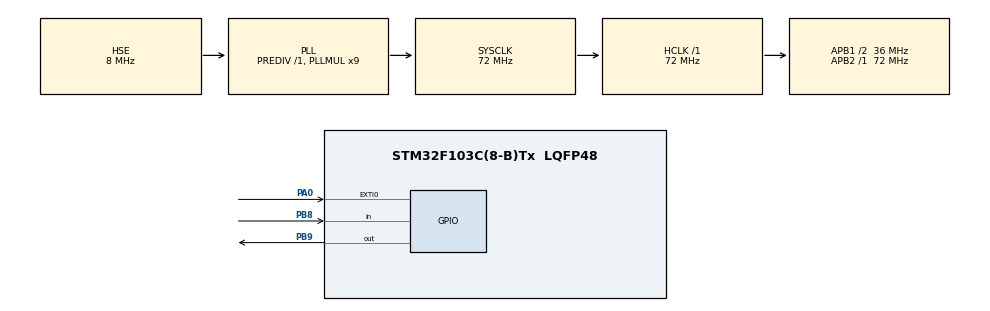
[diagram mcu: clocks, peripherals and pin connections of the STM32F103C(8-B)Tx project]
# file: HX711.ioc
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Mcu.Family=STM32F1
Mcu.Name=STM32F103C(8-B)Tx
Mcu.Package=LQFP48
NVIC.PriorityGroup=NVIC_PRIORITYGROUP_4
NVIC.TIM3_IRQn=true\:0\:0\:false\:false\:true\:true\:true\:true
PA0-WKUP.GPIO_ModeDefaultEXTI=GPIO_MODE_IT_FALLING
PA0-WKUP.Signal=GPXTI0
PA13.Mode=Serial_Wire
PA13.Signal=SYS_JTMS-SWDIO
PA14.Mode=Serial_Wire
PA14.Signal=SYS_JTCK-SWCLK
PB8.Signal=GPIO_Input
PB9.Signal=GPIO_Output
PD0-OSC_IN.Mode=HSE-External-Oscillator
PD0-OSC_IN.Signal=RCC_OSC_IN
PD1-OSC_OUT.Mode=HSE-External-Oscillator
PD1-OSC_OUT.Signal=RCC_OSC_OUT
ProjectManager.HeapSize=0x200
ProjectManager.StackSize=0x400
ProjectManager.TargetToolchain=STM32CubeIDE
RCC.AHBFreq_Value=72000000
RCC.APB1CLKDivider=RCC_HCLK_DIV2
RCC.APB1Freq_Value=36000000
RCC.APB1TimFreq_Value=72000000
RCC.APB2Freq_Value=72000000
RCC.APB2TimFreq_Value=72000000
RCC.HCLKFreq_Value=72000000
RCC.PLLMUL=RCC_PLL_MUL9
RCC.PLLSourceVirtual=RCC_PLLSOURCE_HSE
RCC.SYSCLKFreq_VALUE=72000000
RCC.SYSCLKSource=RCC_SYSCLKSOURCE_PLLCLK
RCC.USBFreq_Value=72000000
TIM2.Prescaler=71
TIM3.Period=9999
TIM3.Prescaler=7199
VP_TIM2_VS_ClockSourceINT.Mode=Internal
VP_TIM3_VS_ClockSourceINT.Mode=Internal
board=custom

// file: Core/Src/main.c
/* USER CODE BEGIN Header */
/**
  ******************************************************************************
  * @file           : main.c
  * @brief          : Main program body
  ******************************************************************************
  * @attention
  *
  * Copyright (c) 2025 STMicroelectronics.
  * All rights reserved.
  *
  * This software is licensed under terms that can be found in the LICENSE file
  * in the root directory of this software component.
  * If no LICENSE file comes with this software, it is provided AS-IS.
  *
  ******************************************************************************
  */
/* USER CODE END Header */
#include "main.h"

/* USER CODE BEGIN PD */
#define DT_PIN GPIO_PIN_8
#define DT_PORT GPIOB
#define SCK_PIN GPIO_PIN_9
#define SCK_PORT GPIOB
/* USER CODE END PD */

TIM_HandleTypeDef htim2;
TIM_HandleTypeDef htim3;

/* USER CODE BEGIN PV */
uint32_t tare = 8645755;
float knownOriginal = 74000;  // in milli gram
float knownHX711 = 30108;
int weight;

volatile uint32_t pulse_count = 0; // Biến đếm xung từ cảm biến
float rpm = 0.0f;                  // Biến lưu giá trị RPM
/* USER CODE END PV */

void SystemClock_Config(void);
static void MX_GPIO_Init(void);
static void MX_TIM2_Init(void);
static void MX_TIM3_Init(void);

/* USER CODE BEGIN 0 */

void HAL_GPIO_EXTI_Callback(uint16_t GPIO_Pin)
{
  if(GPIO_Pin == GPIO_PIN_0) // Kiểm tra xem có phải là ngắt từ chân PA0 không
  {
    pulse_count++; // Nếu đúng, tăng biến đếm xung lên 1
  }
}

void HAL_TIM_PeriodElapsedCallback(TIM_HandleTypeDef *htim)
{
  if (htim->Instance == TIM3) // Kiểm tra xem có phải ngắt từ TIM2 không
  {
    // Công thức: RPM = (Số xung / giây) * 60
    // Vì timer ngắt mỗi 1 giây, nên số xung/giây chính là pulse_count
    rpm = pulse_count * 60;

    // Reset biến đếm để bắt đầu chu kỳ đo mới
    pulse_count = 0;
  }
}

void microDelay(uint16_t delay)
{
  __HAL_TIM_SET_COUNTER(&htim2, 0);
  while (__HAL_TIM_GET_COUNTER(&htim2) < delay);
}

int32_t getHX711(void)
{
  uint32_t data = 0;
  uint32_t startTime = HAL_GetTick();
  while(HAL_GPIO_ReadPin(DT_PORT, DT_PIN) == GPIO_PIN_SET)
  {
    if(HAL_GetTick() - startTime > 200)
      return 0;
  }
  for(int8_t len=0; len<24 ; len++)
  {
    HAL_GPIO_WritePin(SCK_PORT, SCK_PIN, GPIO_PIN_SET);
    microDelay(1);
    data = data << 1;
    HAL_GPIO_WritePin(SCK_PORT, SCK_PIN, GPIO_PIN_RESET);
    microDelay(1);
    if(HAL_GPIO_ReadPin(DT_PORT, DT_PIN) == GPIO_PIN_SET)
      data ++;
  }
  data = data ^ 0x800000;
  HAL_GPIO_WritePin(SCK_PORT, SCK_PIN, GPIO_PIN_SET);
  microDelay(1);
  HAL_GPIO_WritePin(SCK_PORT, SCK_PIN, GPIO_PIN_RESET);
  microDelay(1);
  return data;
}

int weigh()
{
  int32_t  total = 0;
  int32_t  samples = 50;
  int milligram;
  float coefficient;
  for(uint16_t i=0 ; i<samples ; i++)
  {
      total += getHX711();
  }
  int32_t average = (int32_t)(total / samples);
  coefficient = knownOriginal / knownHX711;
  milligram = (int)(average-tare)*coefficient;
  return milligram;
}
/* USER CODE END 0 */

int main(void)
{

  /* MCU Configuration--------------------------------------------------------*/

  /* Reset of all peripherals, Initializes the Flash interface and the Systick. */
  HAL_Init();

  /* Configure the system clock */
  SystemClock_Config();

  /* Initialize all configured peripherals */
  MX_GPIO_Init();
  MX_TIM2_Init();
  MX_TIM3_Init();
  /* USER CODE BEGIN 2 */
  HAL_TIM_Base_Start_IT(&htim3); // Khởi động TIM1 ở chế độ ngắt
  HAL_TIM_Base_Start(&htim2);
  HAL_GPIO_WritePin(SCK_PORT, SCK_PIN, GPIO_PIN_SET);
  HAL_Delay(10);
  HAL_GPIO_WritePin(SCK_PORT, SCK_PIN, GPIO_PIN_RESET);
  HAL_Delay(10);

  /* USER CODE END 2 */

  /* Infinite loop */
  while (1)
  {

    /* USER CODE BEGIN 3 */
	    weight = weigh(); // in milligram
  }
  /* USER CODE END 3 */
}

void SystemClock_Config(void)
{
  RCC_OscInitTypeDef RCC_OscInitStruct = {0};
  RCC_ClkInitTypeDef RCC_ClkInitStruct = {0};

  /** Initializes the RCC Oscillators according to the specified parameters
  * in the RCC_OscInitTypeDef structure.
  */
  RCC_OscInitStruct.OscillatorType = RCC_OSCILLATORTYPE_HSE;
  RCC_OscInitStruct.HSEState = RCC_HSE_ON;
  RCC_OscInitStruct.HSEPredivValue = RCC_HSE_PREDIV_DIV1;
  RCC_OscInitStruct.HSIState = RCC_HSI_ON;
  RCC_OscInitStruct.PLL.PLLState = RCC_PLL_ON;
  RCC_OscInitStruct.PLL.PLLSource = RCC_PLLSOURCE_HSE;
  RCC_OscInitStruct.PLL.PLLMUL = RCC_PLL_MUL9;
  if (HAL_RCC_OscConfig(&RCC_OscInitStruct) != HAL_OK)
  {
    Error_Handler();
  }

  /** Initializes the CPU, AHB and APB buses clocks
  */
  RCC_ClkInitStruct.ClockType = RCC_CLOCKTYPE_HCLK|RCC_CLOCKTYPE_SYSCLK
                              |RCC_CLOCKTYPE_PCLK1|RCC_CLOCKTYPE_PCLK2;
  RCC_ClkInitStruct.SYSCLKSource = RCC_SYSCLKSOURCE_PLLCLK;
  RCC_ClkInitStruct.AHBCLKDivider = RCC_SYSCLK_DIV1;
  RCC_ClkInitStruct.APB1CLKDivider = RCC_HCLK_DIV2;
  RCC_ClkInitStruct.APB2CLKDivider = RCC_HCLK_DIV1;

  if (HAL_RCC_ClockConfig(&RCC_ClkInitStruct, FLASH_LATENCY_2) != HAL_OK)
  {
    Error_Handler();
  }
}

static void MX_TIM2_Init(void)
{

  TIM_ClockConfigTypeDef sClockSourceConfig = {0};
  TIM_MasterConfigTypeDef sMasterConfig = {0};

  htim2.Instance = TIM2;
  htim2.Init.Prescaler = 71;
  htim2.Init.CounterMode = TIM_COUNTERMODE_UP;
  htim2.Init.Period = 65535;
  htim2.Init.ClockDivision = TIM_CLOCKDIVISION_DIV1;
  htim2.Init.AutoReloadPreload = TIM_AUTORELOAD_PRELOAD_DISABLE;
  if (HAL_TIM_Base_Init(&htim2) != HAL_OK)
  {
    Error_Handler();
  }
  sClockSourceConfig.ClockSource = TIM_CLOCKSOURCE_INTERNAL;
  if (HAL_TIM_ConfigClockSource(&htim2, &sClockSourceConfig) != HAL_OK)
  {
    Error_Handler();
  }
  sMasterConfig.MasterOutputTrigger = TIM_TRGO_RESET;
  sMasterConfig.MasterSlaveMode = TIM_MASTERSLAVEMODE_DISABLE;
  if (HAL_TIMEx_MasterConfigSynchronization(&htim2, &sMasterConfig) != HAL_OK)
  {
    Error_Handler();
  }

}

static void MX_TIM3_Init(void)
{

  TIM_ClockConfigTypeDef sClockSourceConfig = {0};
  TIM_MasterConfigTypeDef sMasterConfig = {0};

  htim3.Instance = TIM3;
  htim3.Init.Prescaler = 7199;
  htim3.Init.CounterMode = TIM_COUNTERMODE_UP;
  htim3.Init.Period = 9999;
  htim3.Init.ClockDivision = TIM_CLOCKDIVISION_DIV1;
  htim3.Init.AutoReloadPreload = TIM_AUTORELOAD_PRELOAD_DISABLE;
  if (HAL_TIM_Base_Init(&htim3) != HAL_OK)
  {
    Error_Handler();
  }
  sClockSourceConfig.ClockSource = TIM_CLOCKSOURCE_INTERNAL;
  if (HAL_TIM_ConfigClockSource(&htim3, &sClockSourceConfig) != HAL_OK)
  {
    Error_Handler();
  }
  sMasterConfig.MasterOutputTrigger = TIM_TRGO_RESET;
  sMasterConfig.MasterSlaveMode = TIM_MASTERSLAVEMODE_DISABLE;
  if (HAL_TIMEx_MasterConfigSynchronization(&htim3, &sMasterConfig) != HAL_OK)
  {
    Error_Handler();
  }

}

static void MX_GPIO_Init(void)
{
  GPIO_InitTypeDef GPIO_InitStruct = {0};

  /* GPIO Ports Clock Enable */
  __HAL_RCC_GPIOD_CLK_ENABLE();
  __HAL_RCC_GPIOA_CLK_ENABLE();
  __HAL_RCC_GPIOB_CLK_ENABLE();

  /*Configure GPIO pin Output Level */
  HAL_GPIO_WritePin(GPIOB, GPIO_PIN_9, GPIO_PIN_RESET);

  /*Configure GPIO pin : PA0 */
  GPIO_InitStruct.Pin = GPIO_PIN_0;
  GPIO_InitStruct.Mode = GPIO_MODE_IT_FALLING;
  GPIO_InitStruct.Pull = GPIO_NOPULL;
  HAL_GPIO_Init(GPIOA, &GPIO_InitStruct);

  /*Configure GPIO pin : PB8 */
  GPIO_InitStruct.Pin = GPIO_PIN_8;
  GPIO_InitStruct.Mode = GPIO_MODE_INPUT;
  GPIO_InitStruct.Pull = GPIO_NOPULL;
  HAL_GPIO_Init(GPIOB, &GPIO_InitStruct);

  /*Configure GPIO pin : PB9 */
  GPIO_InitStruct.Pin = GPIO_PIN_9;
  GPIO_InitStruct.Mode = GPIO_MODE_OUTPUT_PP;
  GPIO_InitStruct.Pull = GPIO_NOPULL;
  GPIO_InitStruct.Speed = GPIO_SPEED_FREQ_LOW;
  HAL_GPIO_Init(GPIOB, &GPIO_InitStruct);

}

void Error_Handler(void)
{
  __disable_irq();
  while (1)
  {
  }
}
